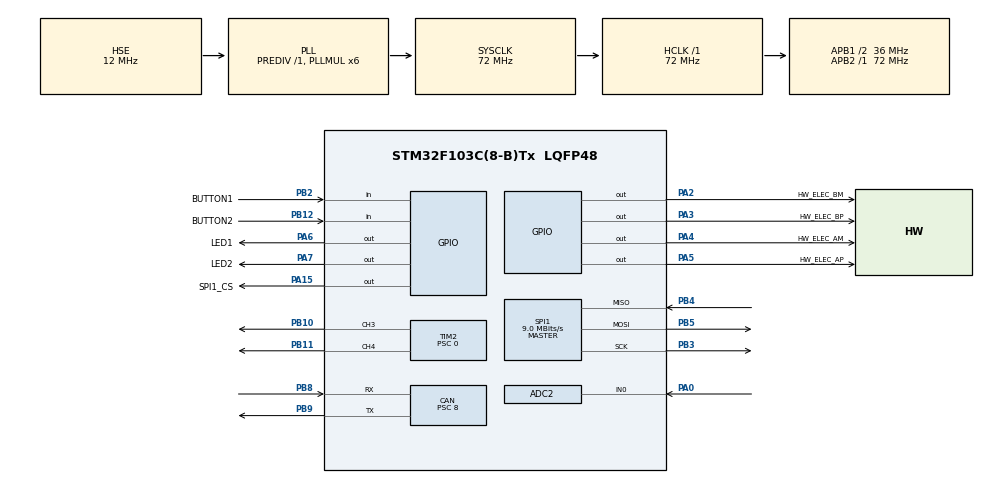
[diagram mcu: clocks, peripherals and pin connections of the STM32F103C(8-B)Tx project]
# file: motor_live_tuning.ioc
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ADC1.Channel-1\#ChannelRegularConversion=ADC_CHANNEL_TEMPSENSOR
ADC1.ContinuousConvMode=DISABLE
ADC1.NbrOfConversionFlag=1
ADC1.Rank-1\#ChannelRegularConversion=1
ADC1.SamplingTime-1\#ChannelRegularConversion=ADC_SAMPLETIME_13CYCLES_5
ADC1.master=1
ADC2.Channel-0\#ChannelRegularConversion=ADC_CHANNEL_0
ADC2.ContinuousConvMode=DISABLE
ADC2.NbrOfConversionFlag=1
ADC2.Rank-0\#ChannelRegularConversion=1
ADC2.SamplingTime-0\#ChannelRegularConversion=ADC_SAMPLETIME_71CYCLES_5
CAN.BS1=CAN_BS1_6TQ
CAN.BS2=CAN_BS2_2TQ
CAN.CalculateBaudRate=500000
CAN.CalculateTimeBit=2000
CAN.CalculateTimeQuantum=222.22222222222223
CAN.Prescaler=8
Mcu.Family=STM32F1
Mcu.Name=STM32F103C(8-B)Tx
Mcu.Package=LQFP48
NVIC.ADC1_2_IRQn=true\:0\:0\:false\:false\:true\:true\:true\:true
NVIC.PriorityGroup=NVIC_PRIORITYGROUP_4
NVIC.SPI1_IRQn=true\:0\:0\:false\:false\:true\:true\:true\:true
NVIC.TIM1_UP_IRQn=true\:0\:0\:false\:false\:true\:true\:true\:true
NVIC.TIM3_IRQn=true\:0\:0\:false\:false\:true\:true\:true\:true
NVIC.TIM4_IRQn=true\:0\:0\:false\:false\:true\:true\:true\:true
NVIC.USB_LP_CAN1_RX0_IRQn=true\:0\:0\:false\:false\:true\:true\:true\:true
PA0-WKUP.Signal=ADCx_IN0
PA13.Mode=Serial_Wire
PA13.Signal=SYS_JTMS-SWDIO
PA14.Mode=Serial_Wire
PA14.Signal=SYS_JTCK-SWCLK
PA15.GPIO_Label=SPI1_CS
PA15.PinState=GPIO_PIN_SET
PA15.Signal=GPIO_Output
PA2.GPIO_Label=HW_ELEC_BM
PA2.GPIO_Speed=GPIO_SPEED_FREQ_HIGH
PA2.PinState=GPIO_PIN_RESET
PA2.Signal=GPIO_Output
PA3.GPIO_Label=HW_ELEC_BP
PA3.GPIO_Speed=GPIO_SPEED_FREQ_HIGH
PA3.Signal=GPIO_Output
PA4.GPIO_Label=HW_ELEC_AM
PA4.GPIO_Speed=GPIO_SPEED_FREQ_HIGH
PA4.Signal=GPIO_Output
PA5.GPIO_Label=HW_ELEC_AP
PA5.GPIO_Speed=GPIO_SPEED_FREQ_HIGH
PA5.Signal=GPIO_Output
PA6.GPIO_Label=LED1
PA6.Signal=GPIO_Output
PA7.GPIO_Label=LED2
PA7.Signal=GPIO_Output
PB10.Signal=S_TIM2_CH3
PB11.Signal=S_TIM2_CH4
PB12.GPIO_Label=BUTTON2
PB12.GPIO_PuPd=GPIO_PULLUP
PB12.Signal=GPIO_Input
PB2.GPIO_Label=BUTTON1
PB2.GPIO_PuPd=GPIO_PULLUP
PB2.Signal=GPIO_Input
PB3.Mode=Full_Duplex_Master
PB3.Signal=SPI1_SCK
PB4.Mode=Full_Duplex_Master
PB4.Signal=SPI1_MISO
PB5.Mode=Full_Duplex_Master
PB5.Signal=SPI1_MOSI
PB8.Mode=CAN_Activate
PB8.Signal=CAN_RX
PB9.Mode=CAN_Activate
PB9.Signal=CAN_TX
PD0-OSC_IN.Mode=HSE-External-Oscillator
PD0-OSC_IN.Signal=RCC_OSC_IN
PD1-OSC_OUT.Mode=HSE-External-Oscillator
PD1-OSC_OUT.Signal=RCC_OSC_OUT
ProjectManager.HeapSize=0x200
ProjectManager.StackSize=0x400
ProjectManager.TargetToolchain=STM32CubeIDE
RCC.ADCPresc=RCC_ADCPCLK2_DIV8
RCC.AHBFreq_Value=72000000
RCC.APB1CLKDivider=RCC_HCLK_DIV2
RCC.APB1Freq_Value=36000000
RCC.APB1TimFreq_Value=72000000
RCC.APB2Freq_Value=72000000
RCC.APB2TimFreq_Value=72000000
RCC.HCLKFreq_Value=72000000
RCC.HSE_VALUE=12000000
RCC.PLLMUL=RCC_PLL_MUL6
RCC.PLLSourceVirtual=RCC_PLLSOURCE_HSE
RCC.SYSCLKFreq_VALUE=72000000
RCC.SYSCLKSource=RCC_SYSCLKSOURCE_PLLCLK
RCC.USBFreq_Value=72000000
SH.ADCx_IN0.0=ADC2_IN0,IN0
SH.S_TIM2_CH3.0=TIM2_CH3,PWM Generation3 CH3
SH.S_TIM2_CH4.0=TIM2_CH4,PWM Generation4 CH4
SPI1.BaudRatePrescaler=SPI_BAUDRATEPRESCALER_8
SPI1.CLKPhase=SPI_PHASE_2EDGE
SPI1.CLKPolarity=SPI_POLARITY_HIGH
SPI1.CalculateBaudRate=9.0 MBits/s
SPI1.DataSize=SPI_DATASIZE_16BIT
SPI1.Direction=SPI_DIRECTION_2LINES
SPI1.Mode=SPI_MODE_MASTER
SPI1.VirtualType=VM_MASTER
TIM1.Period=999
TIM1.Prescaler=71
TIM2.Channel-PWM\ Generation3\ CH3=TIM_CHANNEL_3
TIM2.Channel-PWM\ Generation4\ CH4=TIM_CHANNEL_4
TIM2.Period=3599
TIM2.Prescaler=0
TIM3.Period=49
TIM3.Prescaler=71
TIM4.Period=999
TIM4.Prescaler=71
VP_ADC1_TempSens_Input.Mode=IN-TempSens
VP_TIM1_VS_ClockSourceINT.Mode=Internal
VP_TIM2_VS_ClockSourceINT.Mode=Internal
VP_TIM3_VS_ClockSourceINT.Mode=Internal
VP_TIM4_VS_ClockSourceINT.Mode=Internal
board=custom

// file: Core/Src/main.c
/* USER CODE BEGIN Header */
/**
  ******************************************************************************
  * @file           : main.c
  * @brief          : Main program body
  ******************************************************************************
  * @attention
  *
  * Copyright (c) 2026 STMicroelectronics.
  * All rights reserved.
  *
  * This software is licensed under terms that can be found in the LICENSE file
  * in the root directory of this software component.
  * If no LICENSE file comes with this software, it is provided AS-IS.
  *
  ******************************************************************************
  */
/* USER CODE END Header */
#include "main.h"
#include "adc.h"
#include "can.h"
#include "spi.h"
#include "tim.h"
#include "gpio.h"

/* USER CODE BEGIN Includes */
#include "app.h"
/* USER CODE END Includes */

void SystemClock_Config(void);

int main(void)
{

  /* MCU Configuration--------------------------------------------------------*/

  /* Reset of all peripherals, Initializes the Flash interface and the Systick. */
  HAL_Init();

  /* Configure the system clock */
  SystemClock_Config();

  /* Initialize all configured peripherals */
  MX_GPIO_Init();
  MX_ADC1_Init();
  MX_CAN_Init();
  MX_SPI1_Init();
  MX_TIM1_Init();
  MX_TIM2_Init();
  MX_TIM3_Init();
  MX_TIM4_Init();
  MX_ADC2_Init();
  /* USER CODE BEGIN 2 */
  App_Init();

  /* USER CODE END 2 */

  /* Infinite loop */
  /* USER CODE BEGIN WHILE */
  while (1)
  {
	  App_Run();
    /* USER CODE END WHILE */

  }
}

void SystemClock_Config(void)
{
  RCC_OscInitTypeDef RCC_OscInitStruct = {0};
  RCC_ClkInitTypeDef RCC_ClkInitStruct = {0};
  RCC_PeriphCLKInitTypeDef PeriphClkInit = {0};

  /** Initializes the RCC Oscillators according to the specified parameters
  * in the RCC_OscInitTypeDef structure.
  */
  RCC_OscInitStruct.OscillatorType = RCC_OSCILLATORTYPE_HSE;
  RCC_OscInitStruct.HSEState = RCC_HSE_ON;
  RCC_OscInitStruct.HSEPredivValue = RCC_HSE_PREDIV_DIV1;
  RCC_OscInitStruct.HSIState = RCC_HSI_ON;
  RCC_OscInitStruct.PLL.PLLState = RCC_PLL_ON;
  RCC_OscInitStruct.PLL.PLLSource = RCC_PLLSOURCE_HSE;
  RCC_OscInitStruct.PLL.PLLMUL = RCC_PLL_MUL6;
  if (HAL_RCC_OscConfig(&RCC_OscInitStruct) != HAL_OK)
  {
    Error_Handler();
  }

  /** Initializes the CPU, AHB and APB buses clocks
  */
  RCC_ClkInitStruct.ClockType = RCC_CLOCKTYPE_HCLK|RCC_CLOCKTYPE_SYSCLK
                              |RCC_CLOCKTYPE_PCLK1|RCC_CLOCKTYPE_PCLK2;
  RCC_ClkInitStruct.SYSCLKSource = RCC_SYSCLKSOURCE_PLLCLK;
  RCC_ClkInitStruct.AHBCLKDivider = RCC_SYSCLK_DIV1;
  RCC_ClkInitStruct.APB1CLKDivider = RCC_HCLK_DIV2;
  RCC_ClkInitStruct.APB2CLKDivider = RCC_HCLK_DIV1;

  if (HAL_RCC_ClockConfig(&RCC_ClkInitStruct, FLASH_LATENCY_2) != HAL_OK)
  {
    Error_Handler();
  }
  PeriphClkInit.PeriphClockSelection = RCC_PERIPHCLK_ADC;
  PeriphClkInit.AdcClockSelection = RCC_ADCPCLK2_DIV8;
  if (HAL_RCCEx_PeriphCLKConfig(&PeriphClkInit) != HAL_OK)
  {
    Error_Handler();
  }
}

/* USER CODE BEGIN 4 */
void HAL_TIM_PeriodElapsedCallback(TIM_HandleTypeDef *htim)
{
	App_OnTimerElapsed(htim);
}

/* USER CODE END 4 */

void Error_Handler(void)
{
  __disable_irq();
  while (1)
  {
  }
}
